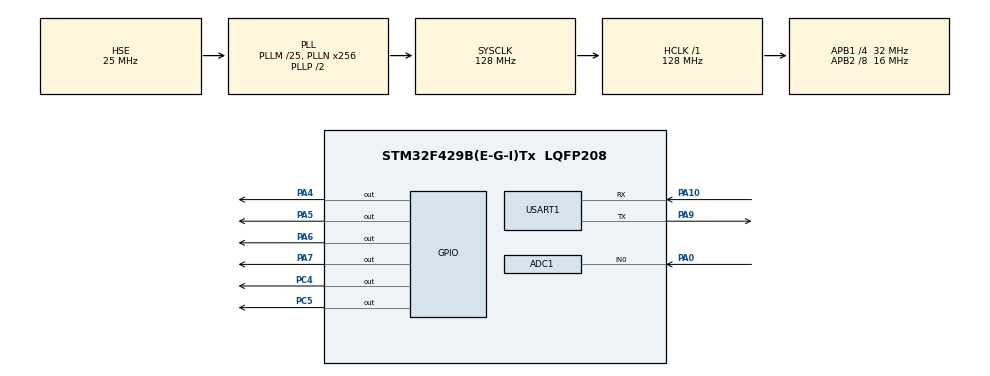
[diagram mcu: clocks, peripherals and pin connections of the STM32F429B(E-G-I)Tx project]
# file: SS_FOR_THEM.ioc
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ADC1.Channel-0\#ChannelRegularConversion=ADC_CHANNEL_0
ADC1.ClockPrescaler=ADC_CLOCK_SYNC_PCLK_DIV4
ADC1.NbrOfConversionFlag=1
ADC1.Rank-0\#ChannelRegularConversion=1
ADC1.SamplingTime-0\#ChannelRegularConversion=ADC_SAMPLETIME_3CYCLES
ADC1.master=1
Mcu.Family=STM32F4
Mcu.Name=STM32F429B(E-G-I)Tx
Mcu.Package=LQFP208
NVIC.PriorityGroup=NVIC_PRIORITYGROUP_4
NVIC.TIM1_BRK_TIM9_IRQn=true\:0\:0\:false\:false\:true\:true\:true
NVIC.TIM1_CC_IRQn=true\:0\:0\:false\:false\:true\:true\:true
NVIC.TIM1_TRG_COM_TIM11_IRQn=true\:0\:0\:false\:false\:true\:true\:true
NVIC.TIM1_UP_TIM10_IRQn=true\:0\:0\:false\:false\:true\:true\:true
NVIC.USART1_IRQn=true\:0\:0\:false\:false\:true\:true\:true
PA0/WKUP.Signal=ADCx_IN0
PA10.Mode=Asynchronous
PA10.Signal=USART1_RX
PA4.Signal=GPIO_Output
PA5.Signal=GPIO_Output
PA6.Signal=GPIO_Output
PA7.Signal=GPIO_Output
PA9.Mode=Asynchronous
PA9.Signal=USART1_TX
PC4.Signal=GPIO_Output
PC5.Signal=GPIO_Output
PH0/OSC_IN.Mode=HSE-External-Oscillator
PH0/OSC_IN.Signal=RCC_OSC_IN
PH1/OSC_OUT.Mode=HSE-External-Oscillator
PH1/OSC_OUT.Signal=RCC_OSC_OUT
ProjectManager.HeapSize=0x200
ProjectManager.StackSize=0x400
ProjectManager.TargetToolchain=MDK-ARM V5.27
RCC.48MHZClocksFreq_Value=64000000
RCC.AHBFreq_Value=128000000
RCC.APB1CLKDivider=RCC_HCLK_DIV4
RCC.APB1Freq_Value=32000000
RCC.APB1TimFreq_Value=64000000
RCC.APB2CLKDivider=RCC_HCLK_DIV8
RCC.APB2Freq_Value=16000000
RCC.APB2TimFreq_Value=32000000
RCC.CortexFreq_Value=128000000
RCC.HCLKFreq_Value=128000000
RCC.HSE_VALUE=25000000
RCC.HSI_VALUE=16000000
RCC.LSE_VALUE=32768
RCC.PLLM=25
RCC.PLLN=256
RCC.PLLSourceVirtual=RCC_PLLSOURCE_HSE
RCC.SYSCLKFreq_VALUE=128000000
RCC.SYSCLKSource=RCC_SYSCLKSOURCE_PLLCLK
RCC.VCOOutputFreq_Value=256000000
SH.ADCx_IN0.0=ADC1_IN0,IN0
TIM1.Period=25-1
TIM1.Prescaler=250-1
USART1.VirtualMode=VM_ASYNC
VP_TIM1_VS_ClockSourceINT.Mode=Internal
board=custom

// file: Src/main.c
/* USER CODE BEGIN Header */
/**
  ******************************************************************************
  * @file           : main.c
  * @brief          : Main program body
  ******************************************************************************
  * @attention
  *
  * <h2><center>&copy; Copyright (c) 2020 STMicroelectronics.
  * All rights reserved.</center></h2>
  *
  * This software component is licensed by ST under BSD 3-Clause license,
  * the "License"; You may not use this file except in compliance with the
  * License. You may obtain a copy of the License at:
  *                        opensource.org/licenses/BSD-3-Clause
  *
  ******************************************************************************
  */
/* USER CODE END Header */

#include "main.h"
#include "adc.h"
#include "tim.h"
#include "usart.h"
#include "gpio.h"

/* USER CODE BEGIN Includes */
#include "stdio.h"
#include "MF_FFT.h"
#include "MF_TIMADC.h"
#include "arm_math.h"
#include "MF_HMI.h"
/* USER CODE END Includes */

void SystemClock_Config(void);

int main(void)
{
  /* USER CODE BEGIN 1 */
int i  = 0 ;
  /* USER CODE END 1 */

  /* MCU Configuration--------------------------------------------------------*/

  /* Reset of all peripherals, Initializes the Flash interface and the Systick. */
  HAL_Init();

  /* Configure the system clock */
  SystemClock_Config();

  /* Initialize all configured peripherals */
  MX_GPIO_Init();
  MX_ADC1_Init();
  MX_TIM1_Init();
  MX_USART1_UART_Init();
  /* USER CODE BEGIN 2 */
	MF_Control_GPIO( GPIO_PIN_SET , GPIO_PIN_RESET , GPIO_PIN_RESET , GPIO_PIN_RESET);

	receiveKey = 0 ;
	HAL_UART_Receive_IT(&huart1,&receiveKey,1);
  /* USER CODE END 2 */

  /* Infinite loop */
  /* USER CODE BEGIN WHILE */
  while (1)
  {
		witchKey();
//		MF_SignalInput();
//		MF_FFT_MagOperation();
//
//		for(i = 0 ; i < Length_Of_FFT ; i++){
//			printf("%d ===>  %.3f\r\n",i ,MF_FFT_Outputbuff[i]);
//		}
//		printf("\r\n\r\n");
    /* USER CODE END WHILE */

  }
}

void SystemClock_Config(void)
{
  RCC_OscInitTypeDef RCC_OscInitStruct = {0};
  RCC_ClkInitTypeDef RCC_ClkInitStruct = {0};

  /** Configure the main internal regulator output voltage
  */
  __HAL_RCC_PWR_CLK_ENABLE();
  __HAL_PWR_VOLTAGESCALING_CONFIG(PWR_REGULATOR_VOLTAGE_SCALE2);
  /** Initializes the CPU, AHB and APB busses clocks
  */
  RCC_OscInitStruct.OscillatorType = RCC_OSCILLATORTYPE_HSE;
  RCC_OscInitStruct.HSEState = RCC_HSE_ON;
  RCC_OscInitStruct.PLL.PLLState = RCC_PLL_ON;
  RCC_OscInitStruct.PLL.PLLSource = RCC_PLLSOURCE_HSE;
  RCC_OscInitStruct.PLL.PLLM = 25;
  RCC_OscInitStruct.PLL.PLLN = 256;
  RCC_OscInitStruct.PLL.PLLP = RCC_PLLP_DIV2;
  RCC_OscInitStruct.PLL.PLLQ = 4;
  if (HAL_RCC_OscConfig(&RCC_OscInitStruct) != HAL_OK)
  {
    Error_Handler();
  }
  /** Initializes the CPU, AHB and APB busses clocks
  */
  RCC_ClkInitStruct.ClockType = RCC_CLOCKTYPE_HCLK|RCC_CLOCKTYPE_SYSCLK
                              |RCC_CLOCKTYPE_PCLK1|RCC_CLOCKTYPE_PCLK2;
  RCC_ClkInitStruct.SYSCLKSource = RCC_SYSCLKSOURCE_PLLCLK;
  RCC_ClkInitStruct.AHBCLKDivider = RCC_SYSCLK_DIV1;
  RCC_ClkInitStruct.APB1CLKDivider = RCC_HCLK_DIV4;
  RCC_ClkInitStruct.APB2CLKDivider = RCC_HCLK_DIV8;

  if (HAL_RCC_ClockConfig(&RCC_ClkInitStruct, FLASH_LATENCY_4) != HAL_OK)
  {
    Error_Handler();
  }
}

void Error_Handler(void)
{
}

/************************ (C) COPYRIGHT STMicroelectronics *****END OF FILE****/
